VERSION "1.0"

NS_ :

BS_:

BU_: ECU1 ECU2 ECU3

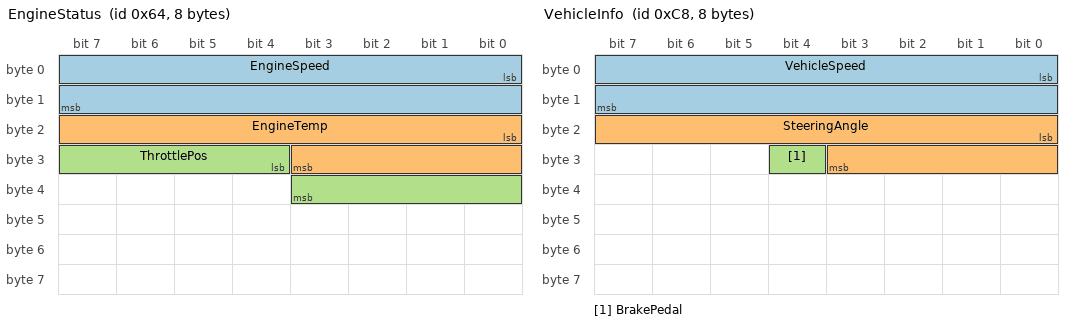
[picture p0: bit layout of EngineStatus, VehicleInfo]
BO_ 100 EngineStatus: 8 ECU1
 SG_ EngineSpeed : 0|16@1+ (0.1,0) [0|8000] "rpm" ECU2,ECU3
 SG_ EngineTemp : 16|12@1+ (0.5,0) [0|150] "C" ECU2
 SG_ ThrottlePos : 28|8@1+ (1,0) [0|100] "%" ECU3

BO_ 200 VehicleInfo: 8 ECU2
 SG_ VehicleSpeed : 0|16@1+ (0.1,0) [0|250] "km/h" ECU1,ECU3
 SG_ SteeringAngle : 16|12@1- (1,0) [-600|600] "deg" ECU1
 SG_ BrakePedal : 28|1@1+ (1,0) [0|1] "" ECU1,ECU3

CM_ BO_ 100 "发动机状态消息，包含转速、温度和油门位置信息";
CM_ SG_ 100 EngineSpeed "发动机转速信号";
CM_ BU_ ECU1 "发动机控制单元";
